AUTOSAR XML (schema 00048)
package /AUTOLIV/SoftwareComponents/PMP
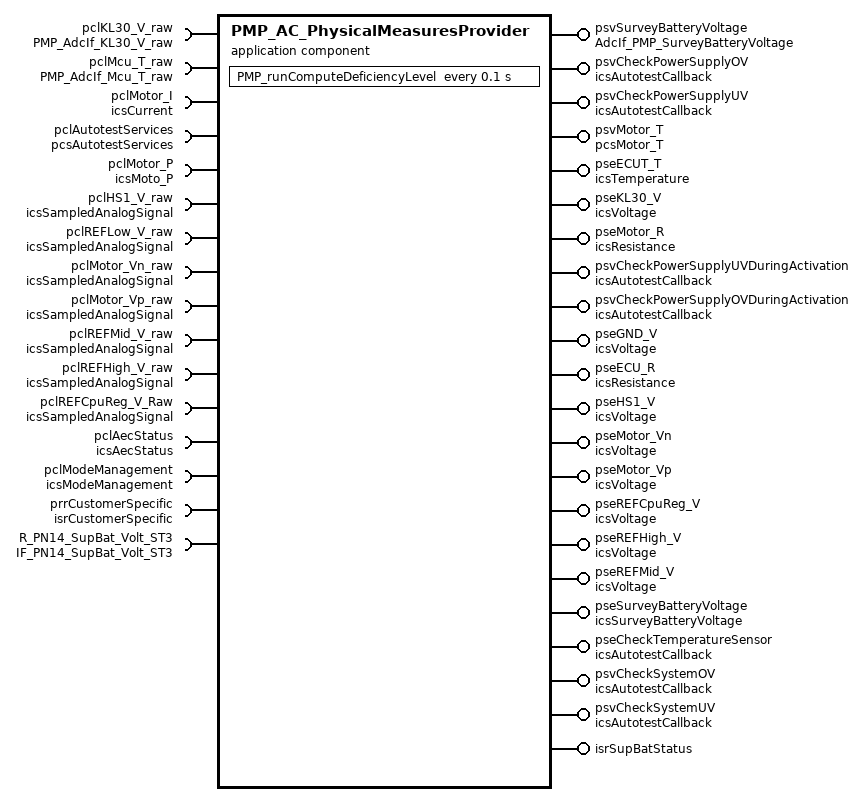
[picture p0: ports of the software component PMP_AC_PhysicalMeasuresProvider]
  application sw component type PMP_AC_PhysicalMeasuresProvider
    provide port psvSurveyBatteryVoltage: server-com-spec{operation=Monitor, queue-length=1}, provided-interface=AdcIf_PMP_SurveyBatteryVoltage
    require port pclKL30_V_raw: required-com-specs=[Get_100ms, Get, Get_10ms, Get_20ms, Get_2ms], required-interface=PMP_AdcIf_KL30_V_raw
    require port pclMcu_T_raw: client-com-spec=Get_10ms, required-interface=PMP_AdcIf_Mcu_T_raw
    provide port psvCheckPowerSupplyOV: server-com-spec{operation=AutotestCallback, queue-length=1}, provided-interface=icsAutotestCallback
    provide port psvCheckPowerSupplyUV: server-com-spec{operation=AutotestCallback, queue-length=1}, provided-interface=icsAutotestCallback
    provide port psvMotor_T: provided-com-specs=[{operation=GetDeficiencyLevel, queue-length=1}, {operation=InitializeDeficiencyLevel, queue-length=1}], provided-interface=pcsMotor_T
    require port pclMotor_I: required-com-specs=[Get_mA, Get_LSB, Get_A, ConvertCurrent_mAtoLSB], required-interface=icsCurrent
    provide port pseECUT_T: provided-interface=icsTemperature
      provided-com-specs:
        operation=Init, queue-length=1
        operation=GetFiltered_deg, queue-length=1
        operation=GetFiltered, queue-length=1
    provide port pseKL30_V: provided-interface=icsVoltage
      provided-com-specs:
        operation=Get_2ms, queue-length=1
        operation=Get_20ms, queue-length=1
        operation=Get_10ms, queue-length=1
        operation=Get_100ms, queue-length=1
        operation=Get, queue-length=1
    provide port pseMotor_R: server-com-spec{operation=Get, queue-length=1}, provided-interface=icsResistance
    require port pclAutotestServices: client-com-spec=GetTestResult, required-interface=pcsAutotestServices
    provide port psvCheckPowerSupplyUVDuringActivation: server-com-spec{operation=AutotestCallback, queue-length=1}, provided-interface=icsAutotestCallback
    provide port psvCheckPowerSupplyOVDuringActivation: server-com-spec{operation=AutotestCallback, queue-length=1}, provided-interface=icsAutotestCallback
    require port pclMotor_P: required-com-specs=[GetPowerOrder, SetPowerOrder], required-interface=icsMoto_P
    9 x provide port:
      pseGND_V: provided-interface=icsVoltage
        provided-com-specs:
          operation=Get, queue-length=1
          operation=Get_100ms, queue-length=1
          operation=Get_10ms, queue-length=1
          operation=Get_20ms, queue-length=1
          operation=Get_2ms, queue-length=1
      pseECU_R: server-com-spec{operation=Get, queue-length=1}, provided-interface=icsResistance
      pseHS1_V: provided-interface=icsVoltage
        provided-com-specs:
          operation=Get, queue-length=1
          operation=Get_100ms, queue-length=1
          operation=Get_10ms, queue-length=1
          operation=Get_20ms, queue-length=1
          operation=Get_2ms, queue-length=1
      pseMotor_Vn: provided-interface=icsVoltage
        provided-com-specs:
          operation=Get, queue-length=1
          operation=Get_100ms, queue-length=1
          operation=Get_10ms, queue-length=1
          operation=Get_20ms, queue-length=1
          operation=Get_2ms, queue-length=1
      pseMotor_Vp: provided-interface=icsVoltage
        provided-com-specs:
          operation=Get, queue-length=1
          operation=Get_100ms, queue-length=1
          operation=Get_10ms, queue-length=1
          operation=Get_20ms, queue-length=1
          operation=Get_2ms, queue-length=1
      pseREFCpuReg_V: provided-interface=icsVoltage
        provided-com-specs:
          operation=Get, queue-length=1
          operation=Get_100ms, queue-length=1
          operation=Get_10ms, queue-length=1
          operation=Get_20ms, queue-length=1
          operation=Get_2ms, queue-length=1
      pseREFHigh_V: provided-interface=icsVoltage
        provided-com-specs:
          operation=Get, queue-length=1
          operation=Get_100ms, queue-length=1
          operation=Get_10ms, queue-length=1
          operation=Get_20ms, queue-length=1
          operation=Get_2ms, queue-length=1
      pseREFMid_V: provided-interface=icsVoltage
        provided-com-specs:
          operation=Get, queue-length=1
          operation=Get_100ms, queue-length=1
          operation=Get_10ms, queue-length=1
          operation=Get_20ms, queue-length=1
          operation=Get_2ms, queue-length=1
      pseSurveyBatteryVoltage: provided-com-specs=[{operation=GetStatus, queue-length=1}, {operation=Monitor, queue-length=1}], provided-interface=icsSurveyBatteryVoltage
    7 x require port, all with required-interface=icsSampledAnalogSignal:
      pclHS1_V_raw: required-com-specs=[Get, Get_100ms, Get_10ms, Get_20ms, Get_2ms]
      pclREFLow_V_raw: required-com-specs=[Get, Get_100ms, Get_10ms, Get_20ms, Get_2ms]
      pclMotor_Vn_raw: required-com-specs=[Get_2ms, Get_20ms, Get_10ms, Get_100ms, Get]
      pclMotor_Vp_raw: required-com-specs=[Get_2ms, Get_20ms, Get_10ms, Get_100ms, Get]
      pclREFMid_V_raw: required-com-specs=[Get_2ms, Get_20ms, Get_10ms, Get_100ms, Get]
      pclREFHigh_V_raw: required-com-specs=[Get_2ms, Get_20ms, Get_10ms, Get_100ms, Get]
      pclREFCpuReg_V_Raw: required-com-specs=[Get_2ms, Get_20ms, Get_10ms, Get_100ms, Get]
    provide port pseCheckTemperatureSensor: server-com-spec{operation=AutotestCallback, queue-length=1}, provided-interface=icsAutotestCallback
    require port pclAecStatus: required-interface=icsAecStatus
      required-com-specs:
        SetAecEvent
        GetNumberOfImplementedAec
        GetAecStatus
        GetAecQualificationCount
        GetAecNvpBlockRecordingStatus
        GetAecGroupsStatus
        GetAecDeskillThrs
    require port pclModeManagement: client-com-spec=CheckModeStatus, required-interface=icsModeManagement
    provide port psvCheckSystemOV: server-com-spec{operation=AutotestCallback, queue-length=1}, provided-interface=icsAutotestCallback
    provide port psvCheckSystemUV: server-com-spec{operation=AutotestCallback, queue-length=1}, provided-interface=icsAutotestCallback
    require port prrCustomerSpecific: required-interface=isrCustomerSpecific
      required-com-specs:
        data-element=b8HardReleaseRequest
        data-element=b8IsCarCrankingActive
        data-element=b8IsCarCrashDetected
        data-element=b8IsTrigOffEventAllowed
        data-element=b8PreCrashRequestEnable
        data-element=u8BeltSlackStatus
        data-element=u8HapticRequest
        data-element=u8PreCrashRequest
        data-element=u8TriggerRequest
        data-element=b8SignalRelInhibition
    require port R_PN14_SupBat_Volt_ST3: nonqueued-receiver-com-spec{data-element=PN14_SupBat_Volt_ST3, init-value=constant-reference=XDIS_9jzhpgyeg4j2n16k3jmfeesjo}, required-interface=IF_PN14_SupBat_Volt_ST3  # Supply battery voltage
    provide port isrSupBatStatus: nonqueued-sender-com-spec=b8SupBatStatus, provided-interface=isrSupBatStatus
    behavior PMP_AC_PhysicalMeasuresProvider_InternalBehavior: data-type-mapping=DataTypeMappingSet_PP4G
      timing event TMT_PMP_runComputeDeficiencyLevel: start-on-event=PMP_runComputeDeficiencyLevel, period=0.1
      init event PMP_AC_PhysicalMeasuresProvider_InitEvent: start-on-event=PMP_Init
      33 x operation invoked event:
        OIT_psvSurveyBatteryVoltage_Monitor_psvSurveyBatteryVoltage_Monitor: start-on-event=PMP_runSurveyBatteryVoltage, operation=psvSurveyBatteryVoltage.Monitor
        OIT_psvMotor_T_GetDeficiencyLevel_psvMotor_T_GetDeficiencyLevel: start-on-event=PMP_runGetDeficiencyLevel, operation=psvMotor_T.GetDeficiencyLevel
        OIT_PMP_runGetBatteryVoltage_pseKL30_V_Get: start-on-event=PMP_runGetBatteryVoltage, operation=pseKL30_V.Get
        OIT_PMP_runGetBatteryVoltage_10ms_pseKL30_V_Get_10ms: start-on-event=PMP_runGetBatteryVoltage_10ms, operation=pseKL30_V.Get_10ms
        OIT_PMP_runGetFilteredTemperature_pseECUT_T_GetFiltered: start-on-event=PMP_runGetFilteredTemperature, operation=pseECUT_T.GetFiltered
        OIT_PMP_runGetMotorResistance_pseECU_R_Get: start-on-event=PMP_runGetMotorResistance, operation=pseMotor_R.Get
        OIT_PMP_runGetFilteredTemperature_deg_pseECUT_T_GetFiltered_deg: start-on-event=PMP_runGetFilteredTemperature_deg, operation=pseECUT_T.GetFiltered_deg
        OIT_PMP_runGetBatteryVoltage_2ms_pseKL30_V_Get_2ms: start-on-event=PMP_runGetBatteryVoltage_2ms, operation=pseKL30_V.Get_2ms
        OIT_PMP_runGetMotorVn_100ms_pseMotor_Vn_Get_100ms: start-on-event=PMP_runGetMotorVn_100ms, operation=pseMotor_Vn.Get_100ms
        OIT_PMP_runGetMotorVn_20ms_pseMotor_Vn_Get_20ms: start-on-event=PMP_runGetMotorVn_20ms, operation=pseMotor_Vn.Get_20ms
        OIT_PMP_runGetCpuRegulatorVoltage_pseREFCpuReg_V_Get: start-on-event=PMP_runGetCpuRegulatorVoltage, operation=pseREFCpuReg_V.Get
        OIT_PMP_runGetBoardResistance_pseECU_R_Get: start-on-event=PMP_runGetBoardResistance, operation=pseECU_R.Get
        OIT_PMP_runGetHS1Level_pseHS1_V_Get: start-on-event=PMP_runGetHS1Level, operation=pseHS1_V.Get
        OIT_PMP_runGetBatteryVoltage_100ms_pseKL30_V_Get_100ms: start-on-event=PMP_runGetBatteryVoltage_100ms, operation=pseKL30_V.Get_100ms
        OIT_PMP_runGetLowReferenceVoltage_100ms_pseGND_V_Get_100ms: start-on-event=PMP_runGetLowReferenceVoltage_100ms, operation=pseGND_V.Get_100ms
        OIT_PMP_runGetLowReferenceVoltage_20ms_pseGND_V_Get_20ms: start-on-event=PMP_runGetLowReferenceVoltage_20ms, operation=pseGND_V.Get_20ms
        OIT_PMP_runGetMotorVp_100ms_pseMotor_Vp_Get_100ms: start-on-event=PMP_runGetMotorVp_100ms, operation=pseMotor_Vp.Get_100ms
        OIT_PMP_runGetMotorVp_20ms_pseMotor_Vp_Get_20ms: start-on-event=PMP_runGetMotorVp_20ms, operation=pseMotor_Vp.Get_20ms
        OIT_PMP_runGetLowReferenceVoltage_pseGND_V_Get: start-on-event=PMP_runGetLowReferenceVoltage, operation=pseGND_V.Get
        OIT_PMP_runGetMotorVp_pseMotor_Vp_Get: start-on-event=PMP_runGetMotorVp, operation=pseMotor_Vp.Get
        OIT_PMP_runGetBatteryVoltage_20ms_pseKL30_V_Get_20ms: start-on-event=PMP_runGetBatteryVoltage_20ms, operation=pseKL30_V.Get_20ms
        OIT_PMP_runGetMotorVn_pseMotor_Vn_Get: start-on-event=PMP_runGetMotorVn, operation=pseMotor_Vn.Get
        OIT_PMP_runGetMidReferenceVoltage_pseREFMid_V_Get: start-on-event=PMP_runGetMidReferenceVoltage, operation=pseREFMid_V.Get
        OIT_PMP_runGetHighReferenceVoltage_pseREFHigh_V_Get: start-on-event=PMP_runGetHighReferenceVoltage, operation=pseREFHigh_V.Get
        OIT_PMP_Autotest_CheckPowerSupplyOV_psvCheckPowerSupplyOV_AutotestCallback: start-on-event=PMP_Autotest_CheckPowerSupplyOV, operation=psvCheckPowerSupplyOV.AutotestCallback
        OIT_PMP_Autotest_CheckPowerSupplyOVDuringActivation_psvCheckPowerSupplyOVDuringActivation_AutotestCallback: start-on-event=PMP_Autotest_CheckPowerSupplyOVDuringActivation, operation=psvCheckPowerSupplyOVDuringActivation.AutotestCallback
        OIT_PMP_Autotest_CheckPowerSupplyUV_psvCheckPowerSupplyUV_AutotestCallback: start-on-event=PMP_Autotest_CheckPowerSupplyUV, operation=psvCheckPowerSupplyUV.AutotestCallback
        OIT_PMP_Autotest_CheckPowerSupplyUVDuringActivation_psvCheckPowerSupplyUVDuringActivation_AutotestCallback: start-on-event=PMP_Autotest_CheckPowerSupplyUVDuringActivation, operation=psvCheckPowerSupplyUVDuringActivation.AutotestCallback
        OIT_PMP_Autotest_CheckTemperatureSensor_pseCheckTemperatureSensor_AutotestCallback: start-on-event=PMP_Autotest_CheckTemperatureSensor, operation=pseCheckTemperatureSensor.AutotestCallback
        OIT_PMP_runInitializeDeficiencyLevel_psvMotor_T_InitializeDeficiencyLevel: start-on-event=PMP_runInitializeDeficiencyLevel, operation=psvMotor_T.InitializeDeficiencyLevel
        OIT_PMP_runGetBatteryVoltageSurveyStatus_pseSurveyBatteryVoltage_GetStatus: start-on-event=PMP_runGetBatteryVoltageSurveyStatus, operation=pseSurveyBatteryVoltage.GetStatus
        OIT_PMP_Autotest_CheckSystemOV_psvCheckSystemOV_AutotestCallback: start-on-event=PMP_Autotest_CheckSystemOV, operation=psvCheckSystemOV.AutotestCallback
        OIT_PMP_Autotest_CheckSystemUV_psvCheckSystemUV_AutotestCallback: start-on-event=PMP_Autotest_CheckSystemUV, operation=psvCheckSystemUV.AutotestCallback
      explicit-inter-runnable-variables:
        5 x data, all with init-value=0:
          u8TestResult: type=u8TestResultType
          u32DeficiencyLevel: type=u32DeficiencyLevelType
          u8EventStatusExtended: type=Dem_EventStatusExtendedType
          u8BatteryVoltageSurveyStatus: type=u8BatteryVoltageSurveyStatusType
          u8AutoTestId: type=u8AutoTestIdType
      35 x runnable:
        PMP_runComputeDeficiencyLevel
          read-local-variables:
            access Read_u32DeficiencyLevel: accessed-variable=u32DeficiencyLevel
          sync call SC_pclMcu_T_raw_Get_10ms: operation=pclMcu_T_raw.Get_10ms
          sync call SC_pclKL30_V_raw_Get_10ms: operation=pclKL30_V_raw.Get_10ms
          sync call SC_pclMotor_I_Get_A: operation=pclMotor_I.Get_A
          written-local-variables:
            access WRITE_u32DeficiencyLevel: accessed-variable=u32DeficiencyLevel
        PMP_Init
          15 x sync call:
            SC_pclHS1_V_raw_Get: operation=pclHS1_V_raw.Get
            SC_pclKL30_V_raw_Get: operation=pclKL30_V_raw.Get
            SC_pclMotor_I_Get_A: operation=pclMotor_I.Get_A
            SC_pclMotor_Vn_raw_Get: operation=pclMotor_Vn_raw.Get
            SC_pclMotor_Vp_raw_Get: operation=pclMotor_Vp_raw.Get
            SC_pclREFCpuReg_V_Raw_Get: operation=pclREFCpuReg_V_Raw.Get
            SC_pclREFHigh_V_raw_Get: operation=pclREFHigh_V_raw.Get
            SC_pclREFLow_V_raw_Get: operation=pclREFLow_V_raw.Get
            SC_pclREFMid_V_raw_Get: operation=pclREFMid_V_raw.Get
            SC_pclKL30_V_raw_Get_20ms: operation=pclKL30_V_raw.Get_20ms
            SC_pclMotor_Vn_raw_Get_20ms: operation=pclMotor_Vn_raw.Get_20ms
            SC_pclMotor_Vp_raw_Get_20ms: operation=pclMotor_Vp_raw.Get_20ms
            SC_pclMotor_Vn_raw_Get_100ms: operation=pclMotor_Vn_raw.Get_100ms
            SC_pclMotor_Vp_raw_Get_100ms: operation=pclMotor_Vp_raw.Get_100ms
            SC_pclModeManagement_CheckModeStatus: operation=pclModeManagement.CheckModeStatus
        PMP_runSurveyBatteryVoltage: can-be-invoked-concurrently=true
          sync call SC_pclKL30_V_raw_Get: operation=pclKL30_V_raw.Get
        PMP_Autotest_CheckPowerSupplyOV
          sync call SC_pclKL30_V_raw_Get_100ms: operation=pclKL30_V_raw.Get_100ms
          sync call SC_pclAutotestServices_GetTestResult: operation=pclAutotestServices.GetTestResult
          sync call SC_pclAecStatus_GetAecStatus: operation=pclAecStatus.GetAecStatus
        PMP_Autotest_CheckPowerSupplyUV
          sync call SC_pclAutotestServices_GetTestResult: operation=pclAutotestServices.GetTestResult
        PMP_runGetDeficiencyLevel
          read-local-variables:
            access Read_u32DeficiencyLevel: accessed-variable=u32DeficiencyLevel
        PMP_runGetFilteredTemperature: can-be-invoked-concurrently=true
        PMP_runGetBatteryVoltage: can-be-invoked-concurrently=true
        PMP_runGetBatteryVoltage_2ms: can-be-invoked-concurrently=true
          sync call SC_pclKL30_V_raw_Get_2ms: operation=pclKL30_V_raw.Get_2ms
        PMP_runGetBatteryVoltage_10ms: can-be-invoked-concurrently=true
          sync call SC_pclKL30_V_raw_Get_10ms: operation=pclKL30_V_raw.Get_10ms
        PMP_runGetMotorResistance: can-be-invoked-concurrently=true
        PMP_runGetFilteredTemperature_deg: can-be-invoked-concurrently=true
        PMP_Autotest_CheckPowerSupplyOVDuringActivation
          sync call SC_pclAutotestServices_GetTestResult: operation=pclAutotestServices.GetTestResult
        PMP_Autotest_CheckPowerSupplyUVDuringActivation
          data-receive-point-by-arguments:
            access REC_prrCustomerSpecific_u8TriggerRequest: accessed-variable=prrCustomerSpecific.u8TriggerRequest
          sync call SC_pclAutotestServices_GetTestResult: operation=pclAutotestServices.GetTestResult
        PMP_runGetMotorVn_100ms: can-be-invoked-concurrently=true
        PMP_runGetMotorVn_20ms: can-be-invoked-concurrently=true
        PMP_runGetCpuRegulatorVoltage: can-be-invoked-concurrently=true
        PMP_runGetBoardResistance: can-be-invoked-concurrently=true
        PMP_runGetHS1Level: can-be-invoked-concurrently=true
        PMP_runGetBatteryVoltage_100ms: can-be-invoked-concurrently=true
        PMP_runGetLowReferenceVoltage_100ms: can-be-invoked-concurrently=true
        PMP_runGetLowReferenceVoltage_20ms: can-be-invoked-concurrently=true
        PMP_runGetMotorVp_100ms: can-be-invoked-concurrently=true
        PMP_runGetMotorVp_20ms: can-be-invoked-concurrently=true
        PMP_runGetLowReferenceVoltage: can-be-invoked-concurrently=true
        PMP_runGetMotorVp: can-be-invoked-concurrently=true
        PMP_runGetBatteryVoltage_20ms: can-be-invoked-concurrently=true
        PMP_runGetMotorVn: can-be-invoked-concurrently=true
        PMP_runGetMidReferenceVoltage: can-be-invoked-concurrently=true
        PMP_runGetHighReferenceVoltage: can-be-invoked-concurrently=true
        PMP_Autotest_CheckTemperatureSensor
        PMP_runInitializeDeficiencyLevel
          written-local-variables:
            access WRITE_u32DeficiencyLevel: accessed-variable=u32DeficiencyLevel
        PMP_runGetBatteryVoltageSurveyStatus: can-be-invoked-concurrently=true
        PMP_Autotest_CheckSystemOV
          data-receive-point-by-arguments:
            access REC_R_PN14_SupBat_Volt_ST3_PN14_SupBat_Volt_ST3: accessed-variable=R_PN14_SupBat_Volt_ST3.PN14_SupBat_Volt_ST3
          data-send-points:
            access SEND_isrSupBatStatus_b8EngStartStatus: accessed-variable=isrSupBatStatus.b8SupBatStatus
          sync call SC_pclAutotestServices_GetTestResult: operation=pclAutotestServices.GetTestResult
        PMP_Autotest_CheckSystemUV
          sync call SC_pclAutotestServices_GetTestResult: operation=pclAutotestServices.GetTestResult
  swc implementation PMP_AC_PhysicalMeasuresProvider_Implementation: behavior=PMP_AC_PhysicalMeasuresProvider_InternalBehavior
